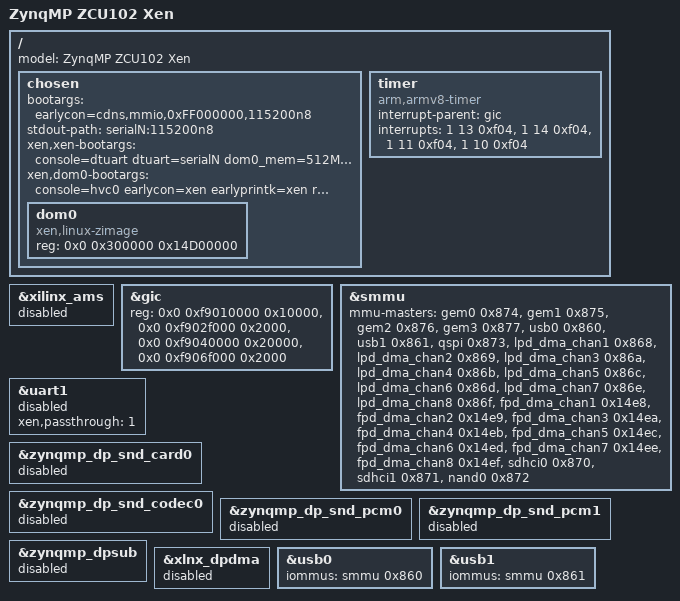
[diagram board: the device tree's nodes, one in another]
/*
 * dts file for Xilinx ZynqMP ZCU102 Board Running Xen
 *
 * Copyright (c) 2017 DornerWorks
 *
 * Permission is hereby granted, free of charge, to any person obtaining a copy
 * of this software and associated documentation files (the "Software"), to deal
 * in the Software without restriction, including without limitation the rights
 * to use, copy, modify, merge, publish, distribute, sublicense, and/or sell
 * copies of the Software, and to permit persons to whom the Software is
 * furnished to do so, subject to the following conditions:
 *
 * The above copyright notice and this permission notice shall be included in
 * all copies or substantial portions of the Software.
 *
 * THE SOFTWARE IS PROVIDED "AS IS", WITHOUT WARRANTY OF ANY KIND, EXPRESS OR
 * IMPLIED, INCLUDING BUT NOT LIMITED TO THE WARRANTIES OF MERCHANTABILITY,
 * FITNESS FOR A PARTICULAR PURPOSE AND NONINFRINGEMENT. IN NO EVENT SHALL THE
 * AUTHORS OR COPYRIGHT HOLDERS BE LIABLE FOR ANY CLAIM, DAMAGES OR OTHER
 * LIABILITY, WHETHER IN AN ACTION OF CONTRACT, TORT OR OTHERWISE, ARISING FROM,
 * OUT OF OR IN CONNECTION WITH THE SOFTWARE OR THE USE OR OTHER DEALINGS IN
 * THE SOFTWARE.
 */

#include "system-top.dts"

/ {
    model = "ZynqMP ZCU102 Xen";

    chosen {
        bootargs = "earlycon=cdns,mmio,0xFF000000,115200n8";
        stdout-path = "serialN:115200n8";
        #address-cells = <0x2>;
        #size-cells = <0x1>;
        xen,xen-bootargs = "console=dtuart dtuart=serialN dom0_mem=512M bootscrub=0 dom0_vcpus_pin maxcpus=2 timer_slop=0 dom0_max_vcpus=2";
        xen,dom0-bootargs = "console=hvc0 earlycon=xen earlyprintk=xen rootdelay=1 root=/dev/ram devtmpfs.mount=1 clk_ignore_unused";

        dom0 {
            compatible = "xen,linux-zimage", "xen,multiboot-module";
            reg = <0x0 0x300000 0x14D00000>;
        };
    };
    timer {
        compatible = "arm,armv8-timer";
        interrupt-parent = <&gic>;
        interrupts =  <1 13 0xf04>,
                      <1 14 0xf04>,
                      <1 11 0xf04>,
                      <1 10 0xf04>;
      };
  };

&xilinx_ams {
    status = "disabled";
};

&gic {
    reg = <0x0 0xf9010000 0x10000>,
          <0x0 0xf902f000 0x2000>,
          <0x0 0xf9040000 0x20000>,
          <0x0 0xf906f000 0x2000>;
};

&smmu {
    status = "okay";
    mmu-masters = < &gem0 0x874
            &gem1 0x875
            &gem2 0x876
            &gem3 0x877
            &usb0 0x860
            &usb1 0x861
            &qspi 0x873
            &lpd_dma_chan1 0x868
            &lpd_dma_chan2 0x869
            &lpd_dma_chan3 0x86a
            &lpd_dma_chan4 0x86b
            &lpd_dma_chan5 0x86c
            &lpd_dma_chan6 0x86d
            &lpd_dma_chan7 0x86e
            &lpd_dma_chan8 0x86f
            &fpd_dma_chan1 0x14e8
            &fpd_dma_chan2 0x14e9
            &fpd_dma_chan3 0x14ea
            &fpd_dma_chan4 0x14eb
            &fpd_dma_chan5 0x14ec
            &fpd_dma_chan6 0x14ed
            &fpd_dma_chan7 0x14ee
            &fpd_dma_chan8 0x14ef
            &sdhci0 0x870
            &sdhci1 0x871
            &nand0 0x872>;
};

&uart1 {
    status = "disabled";
    xen,passthrough = <1>;
};

&zynqmp_dp_snd_card0 {
    status = "disabled";
};

&zynqmp_dp_snd_codec0 {
    status = "disabled";
};

&zynqmp_dp_snd_pcm0 {
    status = "disabled";
};

&zynqmp_dp_snd_pcm1 {
    status = "disabled";
};

&zynqmp_dpsub {
    status = "disabled";
};

&xlnx_dpdma {
    status = "disabled";
};

&usb0 {
    #stream-id-cells = <0x1>;
    iommus = <&smmu 0x860>;
};

&usb1 {
    #stream-id-cells = <0x1>;
    iommus = <&smmu 0x861>;
};

